# RP2040 register map
Vendor: Raspberry Pi; File version: 0.1
CPU: CM0PLUS r0p1, little endian, MPU, no FPU, VTOR, 2 interrupt priority bits, 26 interrupts
Registers are 32-bit, read-write, reset 0x0 unless marked. A register's access mark holds for its fields unless they carry their own. Offsets are from the block's base; [hi:lo] are bit positions; lines under a group give offsets from that group; {n}, {i} and the like mark numbered series; 'fields as' and 'values as' point back to an identical list; <NAME> marks a mode.

## DMA — DMA with separate read and write masters
Base 0x50000000
{0x0+0x40*i} CH{i} (i=0..11) group — Cluster CH{i}, containing CH?_READ_ADDR,CH??_READ_ADDR, CH?_WRITE_ADDR,CH??_WRITE_ADDR, CH?_TRANS_COUNT,CH??_TRANS_COUNT, CH?_CTRL_TRIG,CH??_CTRL_TRIG, CH?_AL1_CTRL,CH??_AL1_CTRL, CH?_AL1_READ_ADDR,CH??_AL1_READ_ADDR, CH?_AL1_WRITE_ADDR,CH??_AL1_WRITE_ADDR, CH?_AL1_TRANS_COUNT_TRIG,CH??_AL1_TRANS_COUNT_TRIG, CH?_AL2_CTRL,CH??_AL2_CTRL, CH?_AL2_TRANS_COUNT,CH??_AL2_TRANS_COUNT, CH?_AL2_READ_ADDR,CH??_AL2_READ_ADDR, CH?_AL2_WRITE_ADDR_TRIG,CH??_AL2_WRITE_ADDR_TRIG, CH?_AL3_CTRL,CH??_AL3_CTRL, CH?_AL3_WRITE_ADDR,CH??_AL3_WRITE_ADDR, CH?_AL3_TRANS_COUNT,CH??_AL3_TRANS_COUNT, CH?_AL3_READ_ADDR_TRIG,CH??_AL3_READ_ADDR_TRIG
  0x00 CH_READ_ADDR — DMA Channel 0 Read Address pointer. This register updates automatically each time a read completes. The current value is the next address to be read by this channel.
  0x04 CH_WRITE_ADDR — DMA Channel 0 Write Address pointer. This register updates automatically each time a write completes. The current value is the next address to be written by this channel.
  0x08 CH_TRANS_COUNT — DMA Channel 0 Transfer Count. Program the number of bus transfers a channel will perform before halting. Note that, if transfers are larger than one byte in size, this is not equal to the number of bytes transferred (see CTRL_DATA_SIZE). . When the channel is active, reading this register shows the number of transfers remaining, updating automatically each time a write transfer completes. . Writing this register sets the RELOAD value for the transfer counter. Each time this channel is triggered, the RELOAD value is copied into the live transfer counter. The channel can be started multiple times, and will perform the same number of transfers each time, as programmed by most recent write. . The RELOAD value can be observed at CHx_DBG_TCR. If TRANS_COUNT is used as a trigger, the written value is used immediately as the length of the new transfer sequence, as well as being written to RELOAD.
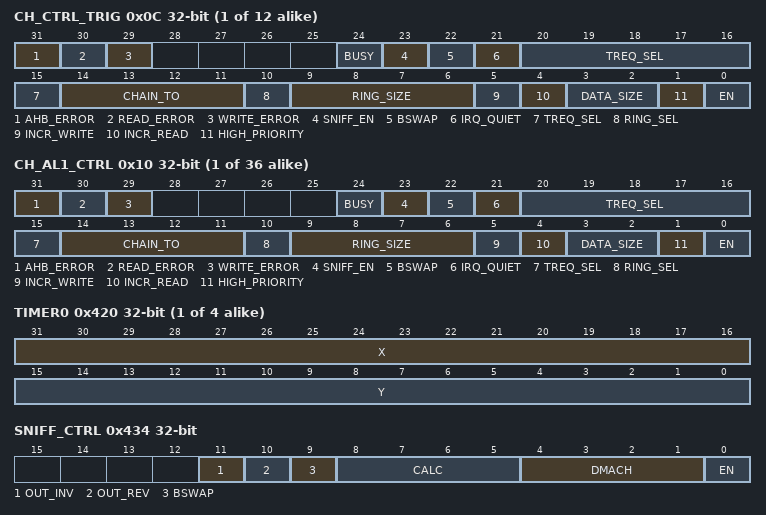
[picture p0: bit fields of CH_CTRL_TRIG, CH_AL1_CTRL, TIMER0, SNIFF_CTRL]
  0x0C CH_CTRL_TRIG access per field — DMA Channel 0 Control and Status
    [31] AHB_ERROR ro — Logical OR of the READ_ERROR and WRITE_ERROR flags. The channel halts when it encounters any bus error, and always raises its channel IRQ flag.
    [30] READ_ERROR rw write-1-clears — If 1, the channel received a read bus error. Write one to clear. READ_ADDR shows the approximate address where the bus error was encountered (will not be earlier, or more than 3 transfers later)
    [29] WRITE_ERROR rw write-1-clears — If 1, the channel received a write bus error. Write one to clear. WRITE_ADDR shows the approximate address where the bus error was encountered (will not be earlier, or more than 5 transfers later)
    [24] BUSY ro — This flag goes high when the channel starts a new transfer sequence, and low when the last transfer of that sequence completes. Clearing EN while BUSY is high pauses the channel, and BUSY will stay high while paused. . To terminate a sequence early (and clear the BUSY flag), see CHAN_ABORT.
    [23] SNIFF_EN rw — If 1, this channel's data transfers are visible to the sniff hardware, and each transfer will advance the state of the checksum. This only applies if the sniff hardware is enabled, and has this channel selected. . This allows checksum to be enabled or disabled on a per-control- block basis.
    [22] BSWAP rw — Apply byte-swap transformation to DMA data. For byte data, this has no effect. For halfword data, the two bytes of each halfword are swapped. For word data, the four bytes of each word are swapped to reverse order.
    [21] IRQ_QUIET rw — In QUIET mode, the channel does not generate IRQs at the end of every transfer block. Instead, an IRQ is raised when NULL is written to a trigger register, indicating the end of a control block chain. . This reduces the number of interrupts to be serviced by the CPU when transferring a DMA chain of many small control blocks.
    [20:15] TREQ_SEL rw — Select a Transfer Request signal. The channel uses the transfer request signal to pace its data transfer rate. Sources for TREQ signals are internal (TIMERS) or external (DREQ, a Data Request from the system). 0x0 to 0x3a -> select DREQ n as TREQ
      {v}=PIO0_TX{v} (Select PIO0's TX FIFO {v} as TREQ) (v=0..3); {v}=PIO0_RX{v-4} (Select PIO0's RX FIFO {v-4} as TREQ) (v=4..7); {v}=PIO1_TX{v-8} (Select PIO1's TX FIFO {v-8} as TREQ) (v=8..11); {v}=PIO1_RX{v-12} (Select PIO1's RX FIFO {v-12} as TREQ) (v=12..15); 16=SPI0_TX (Select SPI0's TX FIFO as TREQ); 17=SPI0_RX (Select SPI0's RX FIFO as TREQ); 18=SPI1_TX (Select SPI1's TX FIFO as TREQ); 19=SPI1_RX (Select SPI1's RX FIFO as TREQ); 20=UART0_TX (Select UART0's TX FIFO as TREQ); 21=UART0_RX (Select UART0's RX FIFO as TREQ); 22=UART1_TX (Select UART1's TX FIFO as TREQ); 23=UART1_RX (Select UART1's RX FIFO as TREQ); {v}=PWM_WRAP{v-24} (Select PWM Counter {v-24}'s Wrap Value as TREQ) (v=24..31); 32=I2C0_TX (Select I2C0's TX FIFO as TREQ); 33=I2C0_RX (Select I2C0's RX FIFO as TREQ); 34=I2C1_TX (Select I2C1's TX FIFO as TREQ); 35=I2C1_RX (Select I2C1's RX FIFO as TREQ); 36=ADC (Select the ADC as TREQ); 37=XIP_STREAM (Select the XIP Streaming FIFO as TREQ); 38=XIP_SSITX (Select the XIP SSI TX FIFO as TREQ); 39=XIP_SSIRX (Select the XIP SSI RX FIFO as TREQ); 59=TIMER0 (Select Timer 0 as TREQ); 60=TIMER1 (Select Timer 1 as TREQ); 61=TIMER2 (Select Timer 2 as TREQ (Optional)); 62=TIMER3 (Select Timer 3 as TREQ (Optional)); 63=PERMANENT (Permanent request, for unpaced transfers.)
    [14:11] CHAIN_TO rw — When this channel completes, it will trigger the channel indicated by CHAIN_TO. Disable by setting CHAIN_TO = _(this channel)_. Reset value is 0, which means for channels 1 and above the default will be to chain to channel 0 - set this field to avoid this behaviour.
    [10] RING_SEL rw — Select whether RING_SIZE applies to read or write addresses. If 0, read addresses are wrapped on a (1 << RING_SIZE) boundary. If 1, write addresses are wrapped.
    [9:6] RING_SIZE rw — Size of address wrap region. If 0, don't wrap. For values n > 0, only the lower n bits of the address will change. This wraps the address on a (1 << n) byte boundary, facilitating access to naturally-aligned ring buffers. . Ring sizes between 2 and 32768 bytes are possible. This can apply to either read or write addresses, based on value of RING_SEL.
      0=RING_NONE
    [5] INCR_WRITE rw — If 1, the write address increments with each transfer. If 0, each write is directed to the same, initial address. . Generally this should be disabled for memory-to-peripheral transfers.
    [4] INCR_READ rw — If 1, the read address increments with each transfer. If 0, each read is directed to the same, initial address. . Generally this should be disabled for peripheral-to-memory transfers.
    [3:2] DATA_SIZE rw — Set the size of each bus transfer (byte/halfword/word). READ_ADDR and WRITE_ADDR advance by this amount (1/2/4 bytes) with each transfer.
      0=SIZE_BYTE; 1=SIZE_HALFWORD; 2=SIZE_WORD
    [1] HIGH_PRIORITY rw — HIGH_PRIORITY gives a channel preferential treatment in issue scheduling: in each scheduling round, all high priority channels are considered first, and then only a single low priority channel, before returning to the high priority channels. . This only affects the order in which the DMA schedules channels. The DMA's bus priority is not changed. If the DMA is not saturated then a low priority channel will see no loss of throughput.
    [0] EN rw — DMA Channel Enable. When 1, the channel will respond to triggering events, which will cause it to become BUSY and start transferring data. When 0, the channel will ignore triggers, stop issuing transfers, and pause the current transfer sequence (i.e. BUSY will remain high if already high)
  {0x0+0x10*j} CH_AL{j}_CTRL access per field (j=1..3) — DMA Channel 0 Control and Status
    fields as CH0.CH_CTRL_TRIG
  0x14 CH_AL1_READ_ADDR — Alias for channel 0 READ_ADDR register
  0x18 CH_AL1_WRITE_ADDR — Alias for channel 0 WRITE_ADDR register
  0x1C CH_AL1_TRANS_COUNT_TRIG — Alias for channel 0 TRANS_COUNT register. This is a trigger register (0xc). Writing a nonzero value will reload the channel counter and start the channel.
  0x24 CH_AL2_TRANS_COUNT — Alias for channel 0 TRANS_COUNT register
  0x28 CH_AL2_READ_ADDR — Alias for channel 0 READ_ADDR register
  0x2C CH_AL2_WRITE_ADDR_TRIG — Alias for channel 0 WRITE_ADDR register. This is a trigger register (0xc). Writing a nonzero value will reload the channel counter and start the channel.
  0x34 CH_AL3_WRITE_ADDR — Alias for channel 0 WRITE_ADDR register
  0x38 CH_AL3_TRANS_COUNT — Alias for channel 0 TRANS_COUNT register
  0x3C CH_AL3_READ_ADDR_TRIG — Alias for channel 0 READ_ADDR register. This is a trigger register (0xc). Writing a nonzero value will reload the channel counter and start the channel.
0x400 INTR — Interrupt Status (raw)
  [15:0] INTR write-1-clears — Raw interrupt status for DMA Channels 0..15. Bit n corresponds to channel n. Ignores any masking or forcing. Channel interrupts can be cleared by writing a bit mask to INTR, INTS0 or INTS1. . Channel interrupts can be routed to either of two system-level IRQs based on INTE0 and INTE1. . This can be used vector different channel interrupts to different ISRs: this might be done to allow NVIC IRQ preemption for more time-critical channels, or to spread IRQ load across different cores. . It is also valid to ignore this behaviour and just use INTE0/INTS0/IRQ 0.
0x404 INTE0 — Interrupt Enables for IRQ 0
  [15:0] INTE0 — Set bit n to pass interrupts from channel n to DMA IRQ 0.
0x408 INTF0 — Force Interrupts
  [15:0] INTF0 — Write 1s to force the corresponding bits in INTE0. The interrupt remains asserted until INTF0 is cleared.
0x40C INTS0 — Interrupt Status for IRQ 0
  [15:0] INTS0 write-1-clears — Indicates active channel interrupt requests which are currently causing IRQ 0 to be asserted. Channel interrupts can be cleared by writing a bit mask here.
0x414 INTE1 — Interrupt Enables for IRQ 1
  [15:0] INTE1 — Set bit n to pass interrupts from channel n to DMA IRQ 1.
0x418 INTF1 — Force Interrupts for IRQ 1
  [15:0] INTF1 — Write 1s to force the corresponding bits in INTE0. The interrupt remains asserted until INTF0 is cleared.
0x41C INTS1 — Interrupt Status (masked) for IRQ 1
  [15:0] INTS1 write-1-clears — Indicates active channel interrupt requests which are currently causing IRQ 1 to be asserted. Channel interrupts can be cleared by writing a bit mask here.
{0x420+4i} TIMER{i} (i=0..3) — Pacing (X/Y) Fractional Timer. The pacing timer produces TREQ assertions at a rate set by ((X/Y) * sys_clk). This equation is evaluated every sys_clk cycles and therefore can only generate TREQs at a rate of 1 per sys_clk (i.e. permanent TREQ) or less.
  [31:16] X — Pacing Timer Dividend. Specifies the X value for the (X/Y) fractional timer.
  [15:0] Y — Pacing Timer Divisor. Specifies the Y value for the (X/Y) fractional timer.
0x430 MULTI_CHAN_TRIGGER — Trigger one or more channels simultaneously
  [15:0] MULTI_CHAN_TRIGGER write-clears — Each bit in this register corresponds to a DMA channel. Writing a 1 to the relevant bit is the same as writing to that channel's trigger register; the channel will start if it is currently enabled and not already busy.
0x434 SNIFF_CTRL — Sniffer Control
  [11] OUT_INV — If set, the result appears inverted (bitwise complement) when read. This does not affect the way the checksum is calculated; the result is transformed on-the-fly between the result register and the bus.
  [10] OUT_REV — If set, the result appears bit-reversed when read. This does not affect the way the checksum is calculated; the result is transformed on-the-fly between the result register and the bus.
  [9] BSWAP — Locally perform a byte reverse on the sniffed data, before feeding into checksum. . Note that the sniff hardware is downstream of the DMA channel byteswap performed in the read master: if channel CTRL_BSWAP and SNIFF_CTRL_BSWAP are both enabled, their effects cancel from the sniffer's point of view.
  [8:5] CALC
    0=CRC32 (Calculate a CRC-32 (IEEE802.3 polynomial)); 1=CRC32R (Calculate a CRC-32 (IEEE802.3 polynomial) with bit reversed data); 2=CRC16 (Calculate a CRC-16-CCITT); 3=CRC16R (Calculate a CRC-16-CCITT with bit reversed data); 14=EVEN (XOR reduction over all data. == 1 if the total 1 population count is odd.); 15=SUM (Calculate a simple 32-bit checksum (addition with a 32 bit accumulator))
  [4:1] DMACH — DMA channel for Sniffer to observe
  [0] EN — Enable sniffer
0x438 SNIFF_DATA — Data accumulator for sniff hardware. Write an initial seed value here before starting a DMA transfer on the channel indicated by SNIFF_CTRL_DMACH. The hardware will update this register each time it observes a read from the indicated channel. Once the channel completes, the final result can be read from this register.
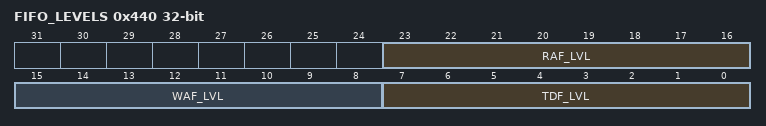
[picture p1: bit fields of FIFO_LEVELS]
0x440 FIFO_LEVELS ro — Debug RAF, WAF, TDF levels
  [23:16] RAF_LVL — Current Read-Address-FIFO fill level
  [15:8] WAF_LVL — Current Write-Address-FIFO fill level
  [7:0] TDF_LVL — Current Transfer-Data-FIFO fill level
0x444 CHAN_ABORT — Abort an in-progress transfer sequence on one or more channels
  [15:0] CHAN_ABORT write-clears — Each bit corresponds to a channel. Writing a 1 aborts whatever transfer sequence is in progress on that channel. The bit will remain high until any in-flight transfers have been flushed through the address and data FIFOs. . After writing, this register must be polled until it returns all-zero. Until this point, it is unsafe to restart the channel.
0x448 N_CHANNELS ro — The number of channels this DMA instance is equipped with. This DMA supports up to 16 hardware channels, but can be configured with as few as one, to minimise silicon area.
  [4:0] N_CHANNELS
{0x800+0x40*i} CH{i}_DBG_CTDREQ (i=0..11) — Read: get channel DREQ counter (i.e. how many accesses the DMA expects it can perform on the peripheral without overflow/underflow. Write any value: clears the counter, and cause channel to re-initiate DREQ handshake.
  [5:0] CH{i}_DBG_CTDREQ write-1-clears
{0x804+0x40*i} CH{i}_DBG_TCR ro (i=0..11) — Read to get channel TRANS_COUNT reload value, i.e. the length of the next transfer
